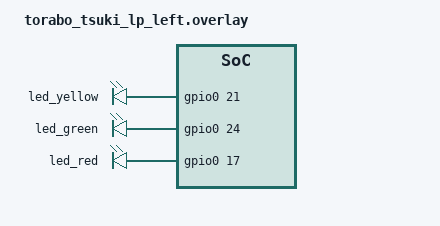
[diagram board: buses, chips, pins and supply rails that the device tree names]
#include "torabo_tsuki_lp.dtsi"
#include <input/processors.dtsi>
#include <dt-bindings/zmk/input_transform.h>
#include <dt-bindings/pinctrl/nrf-pinctrl.h>

&pointing_listener {
    input-processors = <&zip_xy_transform (INPUT_TRANSFORM_X_INVERT | INPUT_TRANSFORM_Y_INVERT)>;
};

/ {
    leds {
        compatible = "gpio-leds";
        led_yellow: led_1 {
            gpios = <&gpio0 21 GPIO_ACTIVE_HIGH>;
        };
        led_green: led_2 {
            gpios = <&gpio0 24 GPIO_ACTIVE_HIGH>;
        };
        led_red: led_3 {
            gpios = <&gpio0 17 GPIO_ACTIVE_HIGH>;
        };
    };

    layer_leds {
        compatible = "zmk,behavior-layer-led";
        
        layer_1 {
            layer = <1>;
            leds = <&led_yellow>;
        };
        layer_2 {
            layer = <2>;
            leds = <&led_green>;
        };
        layer_3 {
            layer = <3>;
            leds = <&led_red>;
        };
    };
};
